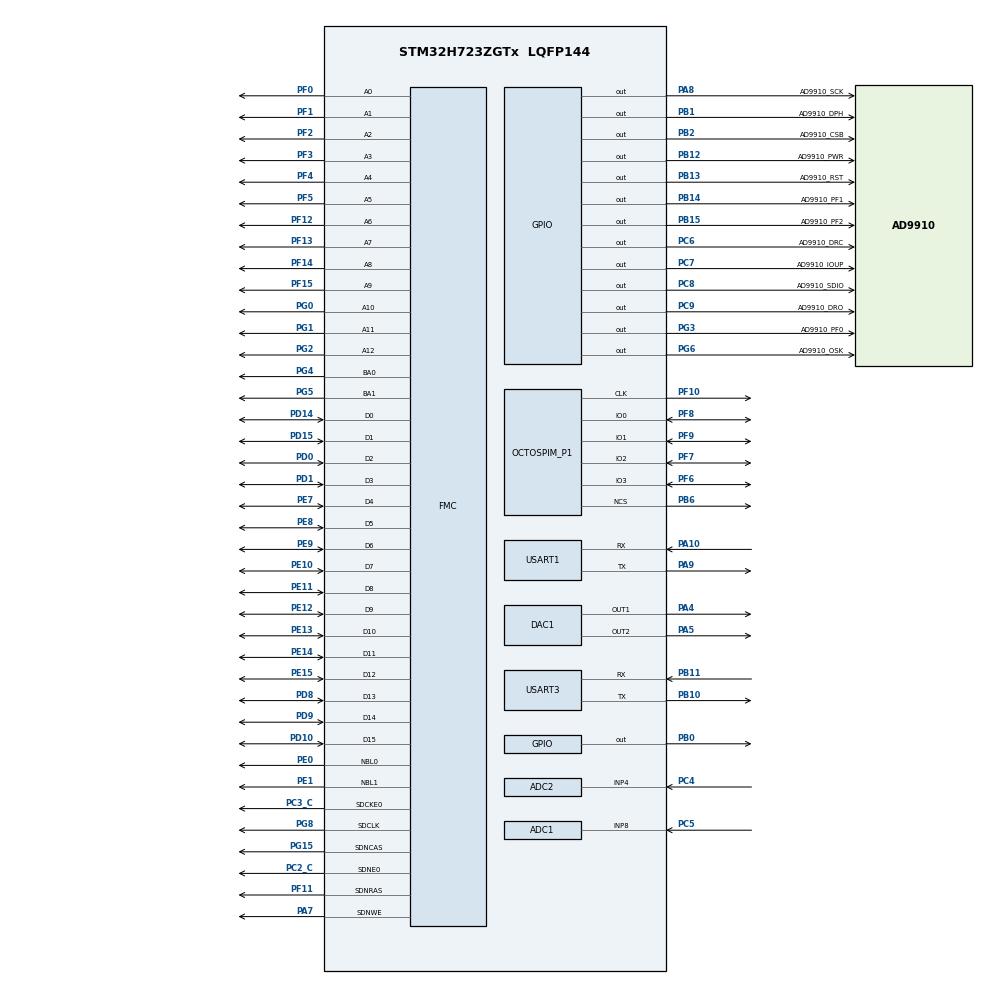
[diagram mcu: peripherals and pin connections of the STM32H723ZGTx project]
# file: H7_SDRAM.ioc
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ADC1.Channel-0\#ChannelRegularConversion=ADC_CHANNEL_8
ADC1.ConversionDataManagement=ADC_CONVERSIONDATA_DMA_ONESHOT
ADC1.ExternalTrigConv=ADC_EXTERNALTRIG_T3_TRGO
ADC1.NbrOfConversionFlag=1
ADC1.OffsetNumber-0\#ChannelRegularConversion=ADC_OFFSET_NONE
ADC1.OffsetSignedSaturation-0\#ChannelRegularConversion=DISABLE
ADC1.Rank-0\#ChannelRegularConversion=1
ADC1.Resolution=ADC_RESOLUTION_12B
ADC1.SamplingTime-0\#ChannelRegularConversion=ADC_SAMPLETIME_2CYCLES_5
ADC1.master=1
ADC2.Channel-0\#ChannelRegularConversion=ADC_CHANNEL_4
ADC2.ClockPrescaler=ADC_CLOCK_ASYNC_DIV1
ADC2.ConversionDataManagement=ADC_CONVERSIONDATA_DMA_ONESHOT
ADC2.ExternalTrigConv=ADC_EXTERNALTRIG_T3_TRGO
ADC2.NbrOfConversionFlag=1
ADC2.OffsetNumber-0\#ChannelRegularConversion=ADC_OFFSET_NONE
ADC2.OffsetSignedSaturation-0\#ChannelRegularConversion=DISABLE
ADC2.Rank-0\#ChannelRegularConversion=1
ADC2.Resolution=ADC_RESOLUTION_12B
ADC2.SamplingTime-0\#ChannelRegularConversion=ADC_SAMPLETIME_2CYCLES_5
CORTEX_M7.AccessPermission_S-Cortex_Memory_Protection_Unit_Region1_Settings_S=MPU_REGION_FULL_ACCESS
CORTEX_M7.AccessPermission_S-Cortex_Memory_Protection_Unit_Region2_Settings_S=MPU_REGION_FULL_ACCESS
CORTEX_M7.AccessPermission_S-Cortex_Memory_Protection_Unit_Region3_Settings_S=MPU_REGION_FULL_ACCESS
CORTEX_M7.AccessPermission_S-Cortex_Memory_Protection_Unit_Region5_Settings_S=MPU_REGION_FULL_ACCESS
CORTEX_M7.AccessPermission_Spec=MPU_REGION_FULL_ACCESS
CORTEX_M7.BaseAddress_S-Cortex_Memory_Protection_Unit_Region1_Settings_S=0x60000000
CORTEX_M7.BaseAddress_S-Cortex_Memory_Protection_Unit_Region2_Settings_S=0x30000000
CORTEX_M7.BaseAddress_S-Cortex_Memory_Protection_Unit_Region3_Settings_S=0x38000000
CORTEX_M7.BaseAddress_S-Cortex_Memory_Protection_Unit_Region5_Settings_S=0xC0000000
CORTEX_M7.BaseAddress_Spec=0x24000000
CORTEX_M7.CPU_DCache=Enabled
CORTEX_M7.CPU_ICache=Enabled
CORTEX_M7.DisableExec_S-Cortex_Memory_Protection_Unit_Region1_Settings_S=MPU_INSTRUCTION_ACCESS_ENABLE
CORTEX_M7.DisableExec_S-Cortex_Memory_Protection_Unit_Region2_Settings_S=MPU_INSTRUCTION_ACCESS_ENABLE
CORTEX_M7.DisableExec_S-Cortex_Memory_Protection_Unit_Region3_Settings_S=MPU_INSTRUCTION_ACCESS_ENABLE
CORTEX_M7.DisableExec_Spec=MPU_INSTRUCTION_ACCESS_ENABLE
CORTEX_M7.Enable_S-Cortex_Memory_Protection_Unit_Region1_Settings_S=MPU_REGION_ENABLE
CORTEX_M7.Enable_S-Cortex_Memory_Protection_Unit_Region2_Settings_S=MPU_REGION_ENABLE
CORTEX_M7.Enable_S-Cortex_Memory_Protection_Unit_Region3_Settings_S=MPU_REGION_ENABLE
CORTEX_M7.Enable_S-Cortex_Memory_Protection_Unit_Region4_Settings_S=__NULL
CORTEX_M7.Enable_S-Cortex_Memory_Protection_Unit_Region5_Settings_S=MPU_REGION_ENABLE
CORTEX_M7.IsBufferable_S-Cortex_Memory_Protection_Unit_Region1_Settings_S=MPU_ACCESS_BUFFERABLE
CORTEX_M7.IsBufferable_S-Cortex_Memory_Protection_Unit_Region2_Settings_S=MPU_ACCESS_BUFFERABLE
CORTEX_M7.IsBufferable_Spec=MPU_ACCESS_BUFFERABLE
CORTEX_M7.IsCacheable_S-Cortex_Memory_Protection_Unit_Region1_Settings_S=MPU_ACCESS_NOT_CACHEABLE
CORTEX_M7.IsCacheable_S-Cortex_Memory_Protection_Unit_Region2_Settings_S=MPU_ACCESS_CACHEABLE
CORTEX_M7.IsCacheable_S-Cortex_Memory_Protection_Unit_Region3_Settings_S=MPU_ACCESS_CACHEABLE
CORTEX_M7.IsCacheable_S-Cortex_Memory_Protection_Unit_Region5_Settings_S=MPU_ACCESS_CACHEABLE
CORTEX_M7.IsCacheable_Spec=MPU_ACCESS_CACHEABLE
CORTEX_M7.IsShareable_Spec=MPU_ACCESS_NOT_SHAREABLE
CORTEX_M7.Size_S-Cortex_Memory_Protection_Unit_Region1_Settings_S=MPU_REGION_SIZE_64KB
CORTEX_M7.Size_S-Cortex_Memory_Protection_Unit_Region2_Settings_S=MPU_REGION_SIZE_64KB
CORTEX_M7.Size_S-Cortex_Memory_Protection_Unit_Region3_Settings_S=MPU_REGION_SIZE_64KB
CORTEX_M7.Size_S-Cortex_Memory_Protection_Unit_Region5_Settings_S=MPU_REGION_SIZE_32MB
CORTEX_M7.Size_Spec=MPU_REGION_SIZE_512KB
CORTEX_M7.SubRegionDisable_S-Cortex_Memory_Protection_Unit_Region1_Settings_S=0x00
CORTEX_M7.SubRegionDisable_Spec=0xE0
CORTEX_M7.TypeExtField_S-Cortex_Memory_Protection_Unit_Region1_Settings_S=MPU_TEX_LEVEL1
CORTEX_M7.TypeExtField_S-Cortex_Memory_Protection_Unit_Region5_Settings_S=MPU_TEX_LEVEL1
CORTEX_M7.TypeExtField_Spec=MPU_TEX_LEVEL1
CORTEX_M7.default_mode_Activation=1
DAC1.DAC_Channel-DAC_OUT1=DAC_CHANNEL_1
DAC1.DAC_Channel-DAC_OUT2=DAC_CHANNEL_2
DAC1.DAC_Trigger-DAC_OUT1=DAC_TRIGGER_T4_TRGO
DAC1.DAC_Trigger-DAC_OUT2=DAC_TRIGGER_T4_TRGO
Dma.ADC1.0.Direction=DMA_PERIPH_TO_MEMORY
Dma.ADC1.0.EventEnable=DISABLE
Dma.ADC1.0.FIFOMode=DMA_FIFOMODE_DISABLE
Dma.ADC1.0.Instance=DMA1_Stream0
Dma.ADC1.0.MemDataAlignment=DMA_MDATAALIGN_HALFWORD
Dma.ADC1.0.MemInc=DMA_MINC_ENABLE
Dma.ADC1.0.Mode=DMA_NORMAL
Dma.ADC1.0.PeriphDataAlignment=DMA_PDATAALIGN_HALFWORD
Dma.ADC1.0.PeriphInc=DMA_PINC_DISABLE
Dma.ADC1.0.Polarity=HAL_DMAMUX_REQ_GEN_RISING
Dma.ADC1.0.Priority=DMA_PRIORITY_HIGH
Dma.ADC1.0.RequestNumber=1
Dma.ADC1.0.SignalID=NONE
Dma.ADC1.0.SyncEnable=DISABLE
Dma.ADC1.0.SyncPolarity=HAL_DMAMUX_SYNC_NO_EVENT
Dma.ADC1.0.SyncRequestNumber=1
Dma.ADC1.0.SyncSignalID=NONE
Dma.ADC2.3.Direction=DMA_PERIPH_TO_MEMORY
Dma.ADC2.3.EventEnable=DISABLE
Dma.ADC2.3.FIFOMode=DMA_FIFOMODE_DISABLE
Dma.ADC2.3.Instance=DMA1_Stream3
Dma.ADC2.3.MemDataAlignment=DMA_MDATAALIGN_HALFWORD
Dma.ADC2.3.MemInc=DMA_MINC_ENABLE
Dma.ADC2.3.Mode=DMA_NORMAL
Dma.ADC2.3.PeriphDataAlignment=DMA_PDATAALIGN_HALFWORD
Dma.ADC2.3.PeriphInc=DMA_PINC_DISABLE
Dma.ADC2.3.Polarity=HAL_DMAMUX_REQ_GEN_RISING
Dma.ADC2.3.Priority=DMA_PRIORITY_HIGH
Dma.ADC2.3.RequestNumber=1
Dma.ADC2.3.SignalID=NONE
Dma.ADC2.3.SyncEnable=DISABLE
Dma.ADC2.3.SyncPolarity=HAL_DMAMUX_SYNC_NO_EVENT
Dma.ADC2.3.SyncRequestNumber=1
Dma.ADC2.3.SyncSignalID=NONE
Dma.DAC1_CH1.4.Direction=DMA_MEMORY_TO_PERIPH
Dma.DAC1_CH1.4.EventEnable=DISABLE
Dma.DAC1_CH1.4.FIFOMode=DMA_FIFOMODE_DISABLE
Dma.DAC1_CH1.4.Instance=DMA1_Stream4
Dma.DAC1_CH1.4.MemDataAlignment=DMA_MDATAALIGN_HALFWORD
Dma.DAC1_CH1.4.MemInc=DMA_MINC_ENABLE
Dma.DAC1_CH1.4.Mode=DMA_CIRCULAR
Dma.DAC1_CH1.4.PeriphDataAlignment=DMA_PDATAALIGN_HALFWORD
Dma.DAC1_CH1.4.PeriphInc=DMA_PINC_DISABLE
Dma.DAC1_CH1.4.Polarity=HAL_DMAMUX_REQ_GEN_RISING
Dma.DAC1_CH1.4.Priority=DMA_PRIORITY_LOW
Dma.DAC1_CH1.4.RequestNumber=1
Dma.DAC1_CH1.4.SignalID=NONE
Dma.DAC1_CH1.4.SyncEnable=DISABLE
Dma.DAC1_CH1.4.SyncPolarity=HAL_DMAMUX_SYNC_NO_EVENT
Dma.DAC1_CH1.4.SyncRequestNumber=1
Dma.DAC1_CH1.4.SyncSignalID=NONE
Dma.DAC1_CH2.5.Direction=DMA_MEMORY_TO_PERIPH
Dma.DAC1_CH2.5.EventEnable=DISABLE
Dma.DAC1_CH2.5.FIFOMode=DMA_FIFOMODE_DISABLE
Dma.DAC1_CH2.5.Instance=DMA1_Stream5
Dma.DAC1_CH2.5.MemDataAlignment=DMA_MDATAALIGN_HALFWORD
Dma.DAC1_CH2.5.MemInc=DMA_MINC_ENABLE
Dma.DAC1_CH2.5.Mode=DMA_CIRCULAR
Dma.DAC1_CH2.5.PeriphDataAlignment=DMA_PDATAALIGN_HALFWORD
Dma.DAC1_CH2.5.PeriphInc=DMA_PINC_DISABLE
Dma.DAC1_CH2.5.Polarity=HAL_DMAMUX_REQ_GEN_RISING
Dma.DAC1_CH2.5.Priority=DMA_PRIORITY_LOW
Dma.DAC1_CH2.5.RequestNumber=1
Dma.DAC1_CH2.5.SignalID=NONE
Dma.DAC1_CH2.5.SyncEnable=DISABLE
Dma.DAC1_CH2.5.SyncPolarity=HAL_DMAMUX_SYNC_NO_EVENT
Dma.DAC1_CH2.5.SyncRequestNumber=1
Dma.DAC1_CH2.5.SyncSignalID=NONE
Dma.Request0=ADC1
Dma.Request1=USART1_RX
Dma.Request2=USART3_RX
Dma.Request3=ADC2
Dma.Request4=DAC1_CH1
Dma.Request5=DAC1_CH2
Dma.USART1_RX.1.Direction=DMA_PERIPH_TO_MEMORY
Dma.USART1_RX.1.EventEnable=DISABLE
Dma.USART1_RX.1.FIFOMode=DMA_FIFOMODE_DISABLE
Dma.USART1_RX.1.Instance=DMA1_Stream1
Dma.USART1_RX.1.MemDataAlignment=DMA_MDATAALIGN_BYTE
Dma.USART1_RX.1.MemInc=DMA_MINC_ENABLE
Dma.USART1_RX.1.Mode=DMA_NORMAL
Dma.USART1_RX.1.PeriphDataAlignment=DMA_PDATAALIGN_BYTE
Dma.USART1_RX.1.PeriphInc=DMA_PINC_DISABLE
Dma.USART1_RX.1.Polarity=HAL_DMAMUX_REQ_GEN_RISING
Dma.USART1_RX.1.Priority=DMA_PRIORITY_HIGH
Dma.USART1_RX.1.RequestNumber=1
Dma.USART1_RX.1.SignalID=NONE
Dma.USART1_RX.1.SyncEnable=DISABLE
Dma.USART1_RX.1.SyncPolarity=HAL_DMAMUX_SYNC_NO_EVENT
Dma.USART1_RX.1.SyncRequestNumber=1
Dma.USART1_RX.1.SyncSignalID=NONE
Dma.USART3_RX.2.Direction=DMA_PERIPH_TO_MEMORY
Dma.USART3_RX.2.EventEnable=DISABLE
Dma.USART3_RX.2.FIFOMode=DMA_FIFOMODE_DISABLE
Dma.USART3_RX.2.Instance=DMA1_Stream2
Dma.USART3_RX.2.MemDataAlignment=DMA_MDATAALIGN_BYTE
Dma.USART3_RX.2.MemInc=DMA_MINC_ENABLE
Dma.USART3_RX.2.Mode=DMA_NORMAL
Dma.USART3_RX.2.PeriphDataAlignment=DMA_PDATAALIGN_BYTE
Dma.USART3_RX.2.PeriphInc=DMA_PINC_DISABLE
Dma.USART3_RX.2.Polarity=HAL_DMAMUX_REQ_GEN_RISING
Dma.USART3_RX.2.Priority=DMA_PRIORITY_HIGH
Dma.USART3_RX.2.RequestNumber=1
Dma.USART3_RX.2.SignalID=NONE
Dma.USART3_RX.2.SyncEnable=DISABLE
Dma.USART3_RX.2.SyncPolarity=HAL_DMAMUX_SYNC_NO_EVENT
Dma.USART3_RX.2.SyncRequestNumber=1
Dma.USART3_RX.2.SyncSignalID=NONE
FMC.CASLatency1=FMC_SDRAM_CAS_LATENCY_3
FMC.ColumnBitsNumber1=FMC_SDRAM_COLUMN_BITS_NUM_9
FMC.ExitSelfRefreshDelay1=10
FMC.LoadToActiveDelay1=2
FMC.RCDDelay1=2
FMC.RPDelay1=3
FMC.RPDelay2=3
FMC.ReadBurst1=FMC_SDRAM_RBURST_ENABLE
FMC.ReadPipeDelay1=FMC_SDRAM_RPIPE_DELAY_1
FMC.ReadPipeDelay2=FMC_SDRAM_RPIPE_DELAY_1
FMC.RowCycleDelay1=9
FMC.RowCycleDelay2=9
FMC.SDClockPeriod1=FMC_SDRAM_CLOCK_PERIOD_2
FMC.SelfRefreshTime1=6
FMC.WriteRecoveryTime1=4
Mcu.Family=STM32H7
Mcu.Name=STM32H723ZGTx
Mcu.Package=LQFP144
NVIC.ADC_IRQn=true\:1\:0\:true\:false\:true\:true\:true\:true
NVIC.DMA1_Stream0_IRQn=true\:0\:0\:false\:false\:true\:false\:true\:true
NVIC.DMA1_Stream1_IRQn=true\:1\:0\:true\:false\:true\:false\:true\:true
NVIC.DMA1_Stream2_IRQn=true\:0\:0\:false\:false\:true\:false\:true\:true
NVIC.DMA1_Stream3_IRQn=true\:0\:0\:false\:false\:true\:false\:true\:true
NVIC.DMA1_Stream4_IRQn=true\:0\:0\:false\:false\:true\:false\:true\:true
NVIC.DMA1_Stream5_IRQn=true\:0\:0\:false\:false\:true\:false\:true\:true
NVIC.PriorityGroup=NVIC_PRIORITYGROUP_4
NVIC.TIM4_IRQn=true\:0\:0\:false\:false\:true\:true\:true\:true
NVIC.TIM6_DAC_IRQn=true\:0\:0\:false\:false\:true\:true\:true\:true
NVIC.USART1_IRQn=true\:0\:0\:false\:false\:true\:true\:true\:true
NVIC.USART3_IRQn=true\:0\:0\:false\:false\:true\:true\:true\:true
OCTOSPI1.ChipSelectHighTime=4
OCTOSPI1.ClockPrescaler=3
OCTOSPI1.DeviceSize=23
OCTOSPI1.FifoThreshold=4
OCTOSPI1.SampleShifting=HAL_OSPI_SAMPLE_SHIFTING_HALFCYCLE
PA10.Mode=Asynchronous
PA10.Signal=USART1_RX
PA4.Signal=COMP_DAC11_group
PA5.Signal=COMP_DAC12_group
PA7.Signal=FMC_SDNWE
PA8.GPIO_Label=AD9910_SCK
PA8.GPIO_Speed=GPIO_SPEED_FREQ_HIGH
PA8.Signal=GPIO_Output
PA9.Mode=Asynchronous
PA9.Signal=USART1_TX
PB0.GPIO_Speed=GPIO_SPEED_FREQ_VERY_HIGH
PB0.PinState=GPIO_PIN_SET
PB0.Signal=GPIO_Output
PB1.GPIO_Label=AD9910_DPH
PB1.GPIO_Speed=GPIO_SPEED_FREQ_HIGH
PB1.Signal=GPIO_Output
PB10.Mode=Asynchronous
PB10.Signal=USART3_TX
PB11.Mode=Asynchronous
PB11.Signal=USART3_RX
PB12.GPIO_Label=AD9910_PWR
PB12.GPIO_Speed=GPIO_SPEED_FREQ_HIGH
PB12.Signal=GPIO_Output
PB13.GPIO_Label=AD9910_RST
PB13.GPIO_Speed=GPIO_SPEED_FREQ_HIGH
PB13.Signal=GPIO_Output
PB14.GPIO_Label=AD9910_PF1
PB14.GPIO_Speed=GPIO_SPEED_FREQ_HIGH
PB14.Signal=GPIO_Output
PB15.GPIO_Label=AD9910_PF2
PB15.GPIO_Speed=GPIO_SPEED_FREQ_HIGH
PB15.Signal=GPIO_Output
PB2.GPIO_Label=AD9910_CSB
PB2.GPIO_Speed=GPIO_SPEED_FREQ_HIGH
PB2.Signal=GPIO_Output
PB6.Mode=OCTOSPI1_Port1_NCS
PB6.Signal=OCTOSPIM_P1_NCS
PC14-OSC32_IN.Mode=LSE-External-Oscillator
PC14-OSC32_IN.Signal=RCC_OSC32_IN
PC15-OSC32_OUT.Mode=LSE-External-Oscillator
PC15-OSC32_OUT.Signal=RCC_OSC32_OUT
PC2_C.Mode=SdramChipSelect1_1
PC2_C.Signal=FMC_SDNE0
PC3_C.Mode=SdramChipSelect1_1
PC3_C.Signal=FMC_SDCKE0
PC4.Signal=ADCx_INP4
PC5.Signal=ADCx_INP8
PC6.GPIO_Label=AD9910_DRC
PC6.GPIO_Speed=GPIO_SPEED_FREQ_HIGH
PC6.Signal=GPIO_Output
PC7.GPIO_Label=AD9910_IOUP
PC7.GPIO_Speed=GPIO_SPEED_FREQ_HIGH
PC7.Signal=GPIO_Output
PC8.GPIO_Label=AD9910_SDIO
PC8.GPIO_Speed=GPIO_SPEED_FREQ_HIGH
PC8.Signal=GPIO_Output
PC9.GPIO_Label=AD9910_DRO
PC9.GPIO_Speed=GPIO_SPEED_FREQ_HIGH
PC9.Signal=GPIO_Output
PD0.Signal=FMC_D2_DA2
PD1.Signal=FMC_D3_DA3
PD10.Signal=FMC_D15_DA15
PD14.Signal=FMC_D0_DA0
PD15.Signal=FMC_D1_DA1
PD8.Signal=FMC_D13_DA13
PD9.Signal=FMC_D14_DA14
PE0.Signal=FMC_NBL0
PE1.Signal=FMC_NBL1
PE10.Signal=FMC_D7_DA7
PE11.Signal=FMC_D8_DA8
PE12.Signal=FMC_D9_DA9
PE13.Signal=FMC_D10_DA10
PE14.Signal=FMC_D11_DA11
PE15.Signal=FMC_D12_DA12
PE7.Signal=FMC_D4_DA4
PE8.Signal=FMC_D5_DA5
PE9.Signal=FMC_D6_DA6
PF0.Signal=FMC_A0
PF1.Signal=FMC_A1
PF10.Mode=O1_P1_CLK
PF10.Signal=OCTOSPIM_P1_CLK
PF11.Signal=FMC_SDNRAS
PF12.Signal=FMC_A6
PF13.Signal=FMC_A7
PF14.Signal=FMC_A8
PF15.Signal=FMC_A9
PF2.Signal=FMC_A2
PF3.Signal=FMC_A3
PF4.Signal=FMC_A4
PF5.Signal=FMC_A5
PF6.Mode=OCTOSPI1_IOL_Port1L
PF6.Signal=OCTOSPIM_P1_IO3
PF7.Mode=OCTOSPI1_IOL_Port1L
PF7.Signal=OCTOSPIM_P1_IO2
PF8.Mode=OCTOSPI1_IOL_Port1L
PF8.Signal=OCTOSPIM_P1_IO0
PF9.Mode=OCTOSPI1_IOL_Port1L
PF9.Signal=OCTOSPIM_P1_IO1
PG0.Signal=FMC_A10
PG1.Signal=FMC_A11
PG15.Signal=FMC_SDNCAS
PG2.Signal=FMC_A12
PG3.GPIO_Label=AD9910_PF0
PG3.GPIO_Speed=GPIO_SPEED_FREQ_HIGH
PG3.Signal=GPIO_Output
PG4.Signal=FMC_A14_BA0
PG5.Signal=FMC_A15_BA1
PG6.GPIO_Label=AD9910_OSK
PG6.GPIO_Speed=GPIO_SPEED_FREQ_HIGH
PG6.Signal=GPIO_Output
PG8.Signal=FMC_SDCLK
PH0-OSC_IN.Mode=HSE-External-Oscillator
PH0-OSC_IN.Signal=RCC_OSC_IN
PH1-OSC_OUT.Mode=HSE-External-Oscillator
PH1-OSC_OUT.Signal=RCC_OSC_OUT
ProjectManager.HeapSize=0x4000
ProjectManager.StackSize=0x4000
ProjectManager.TargetToolchain=MDK-ARM V5.32
RCC.ADCFreq_Value=129000000
RCC.APB1Freq_Value=137500000
RCC.APB2Freq_Value=137500000
RCC.APB3Freq_Value=137500000
RCC.APB4Freq_Value=137500000
RCC.CortexFreq_Value=550000000
RCC.D1PPRE=RCC_APB3_DIV2
RCC.D2PPRE1=RCC_APB1_DIV2
RCC.D2PPRE2=RCC_APB2_DIV2
RCC.D3PPRE=RCC_APB4_DIV2
RCC.DIVM1=4
RCC.DIVN1=34
RCC.DIVP1=1
RCC.HCLKFreq_Value=275000000
RCC.HPRE=RCC_HCLK_DIV2
RCC.PLL2FRACN=0
RCC.PLL3FRACN=0
RCC.PLLFRACN=3072
RCC.SYSCLKFreq_VALUE=550000000
RCC.SYSCLKSource=RCC_SYSCLKSOURCE_PLLCLK
RCC.USBFreq_Value=275000000
SH.ADCx_INP4.0=ADC2_INP4,IN4-Single-Ended
SH.ADCx_INP8.0=ADC1_INP8,IN8-Single-Ended
SH.COMP_DAC11_group.0=DAC1_OUT1,DAC_OUT1
SH.COMP_DAC12_group.0=DAC1_OUT2,DAC_OUT2
SH.FMC_A0.0=FMC_A0,13b-sda1
SH.FMC_A1.0=FMC_A1,13b-sda1
SH.FMC_A10.0=FMC_A10,13b-sda1
SH.FMC_A11.0=FMC_A11,13b-sda1
SH.FMC_A12.0=FMC_A12,13b-sda1
SH.FMC_A14_BA0.0=FMC_BA0,FourSdramBanks1
SH.FMC_A15_BA1.0=FMC_BA1,FourSdramBanks1
SH.FMC_A2.0=FMC_A2,13b-sda1
SH.FMC_A3.0=FMC_A3,13b-sda1
SH.FMC_A4.0=FMC_A4,13b-sda1
SH.FMC_A5.0=FMC_A5,13b-sda1
SH.FMC_A6.0=FMC_A6,13b-sda1
SH.FMC_A7.0=FMC_A7,13b-sda1
SH.FMC_A8.0=FMC_A8,13b-sda1
SH.FMC_A9.0=FMC_A9,13b-sda1
SH.FMC_D0_DA0.0=FMC_D0,sd-16b-d1
SH.FMC_D10_DA10.0=FMC_D10,sd-16b-d1
SH.FMC_D11_DA11.0=FMC_D11,sd-16b-d1
SH.FMC_D12_DA12.0=FMC_D12,sd-16b-d1
SH.FMC_D13_DA13.0=FMC_D13,sd-16b-d1
SH.FMC_D14_DA14.0=FMC_D14,sd-16b-d1
SH.FMC_D15_DA15.0=FMC_D15,sd-16b-d1
SH.FMC_D1_DA1.0=FMC_D1,sd-16b-d1
SH.FMC_D2_DA2.0=FMC_D2,sd-16b-d1
SH.FMC_D3_DA3.0=FMC_D3,sd-16b-d1
SH.FMC_D4_DA4.0=FMC_D4,sd-16b-d1
SH.FMC_D5_DA5.0=FMC_D5,sd-16b-d1
SH.FMC_D6_DA6.0=FMC_D6,sd-16b-d1
SH.FMC_D7_DA7.0=FMC_D7,sd-16b-d1
SH.FMC_D8_DA8.0=FMC_D8,sd-16b-d1
SH.FMC_D9_DA9.0=FMC_D9,sd-16b-d1
SH.FMC_NBL0.0=FMC_NBL0,Sd2ByteEnable1
SH.FMC_NBL1.0=FMC_NBL1,Sd2ByteEnable1
SH.FMC_SDCLK.0=FMC_SDCLK,13b-sda1
SH.FMC_SDNCAS.0=FMC_SDNCAS,13b-sda1
SH.FMC_SDNRAS.0=FMC_SDNRAS,13b-sda1
SH.FMC_SDNWE.0=FMC_SDNWE,13b-sda1
TIM3.AutoReloadPreload=TIM_AUTORELOAD_PRELOAD_ENABLE
TIM3.Period=11-1
TIM3.Prescaler=25-1
TIM3.TIM_MasterOutputTrigger=TIM_TRGO_UPDATE
TIM4.AutoReloadPreload=TIM_AUTORELOAD_PRELOAD_ENABLE
TIM4.Period=5-1
TIM4.Prescaler=8-1
TIM4.TIM_MasterOutputTrigger=TIM_TRGO_UPDATE
USART1.VirtualMode-Asynchronous=VM_ASYNC
USART3.VirtualMode-Asynchronous=VM_ASYNC
VP_MEMORYMAP_VS_MEMORYMAP.Mode=CurAppReg
VP_OCTOSPI1_VS_quad.Mode=quad_mode
VP_TIM3_VS_ClockSourceINT.Mode=Internal
VP_TIM4_VS_ClockSourceINT.Mode=Internal
board=custom

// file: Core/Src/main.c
/* USER CODE BEGIN Header */
/**
  ******************************************************************************
  * @file           : main.c
  * @brief          : Main program body
  ******************************************************************************
  * @attention
  *
  * Copyright (c) 2026 STMicroelectronics.
  * All rights reserved.
  *
  * This software is licensed under terms that can be found in the LICENSE file
  * in the root directory of this software component.
  * If no LICENSE file comes with this software, it is provided AS-IS.
  *
  ******************************************************************************
  */
/* USER CODE END Header */
#include "main.h"
#include "adc.h"
#include "dac.h"
#include "dma.h"
#include "octospi.h"
#include "tim.h"
#include "usart.h"
#include "gpio.h"
#include "fmc.h"

/* USER CODE BEGIN Includes */
#include "bspsysteam.h"

/* USER CODE END Includes */

void SystemClock_Config(void);
void PeriphCommonClock_Config(void);
static void MPU_Config(void);

/* USER CODE BEGIN 0 */

__attribute__((section(".RAM_D1"), aligned(32))) uint16_t adc_1_buffer[FFT_LEN];
__attribute__((section(".RAM_D1"), aligned(32))) uint16_t adc_2_buffer[FFT_LEN];
__attribute__((section(".RAM_D3"))) volatile uint8_t adc1_flag;
__attribute__((section(".RAM_D3")))volatile uint8_t adc2_flag;

__attribute__((section(".RAM_D3"))) float32_t re1;
__attribute__((section(".RAM_D3"))) float32_t im1;
__attribute__((section(".RAM_D3"))) float32_t re2;
__attribute__((section(".RAM_D3"))) float32_t im2;

__attribute__((section(".RAM_D3"))) float32_t phase_1;
__attribute__((section(".RAM_D3"))) float32_t phase_2;
__attribute__((section(".RAM_D3"))) float32_t freq_1;
__attribute__((section(".RAM_D3"))) float32_t freq_2;
__attribute__((section(".RAM_D3"))) float32_t phase_diff;
__attribute__((section(".RAM_D3"))) float32_t phase_diff_deg;

__attribute__((section(".RAM_D3"))) uint32_t dac_freq = 100000;
__attribute__((section(".RAM_D3"))) uint32_t dac_phase=0;
__attribute__((section(".RAM_D3"))) uint32_t dac_amp=800;
/*DMA 整个缓冲区采样完成后*/
void HAL_ADC_ConvCpltCallback(ADC_HandleTypeDef *hadc)
{
	if(hadc->Instance==ADC1)
	{
		if(adc1_flag==0)
			adc1_flag = 1;
	}

	if(hadc->Instance==ADC2)
	{
		if(adc2_flag==0)
			adc2_flag = 1;
	}
}

void FFT_proc(void)
{
		float32_t phase_error = 0.0f;
    if (adc1_flag == 1 && adc2_flag == 1)
    {
        adc1_flag = 0;
        adc2_flag = 0;

        Process_fft(adc_1_buffer,FFT_LEN,&phase_1,&freq_1);
				Process_fft(adc_2_buffer,FFT_LEN,&phase_2,&freq_2);
				phase_diff = phase_1-phase_2;
				if (phase_diff > PI)
				{
				phase_diff -= PI2;
				}
				else if (phase_diff < -PI)
				{
				phase_diff += PI2;
				}
				phase_error = (-0.000362f)*freq_1-(0.02f);
        phase_diff_deg = phase_diff * 180.0f / PI-phase_error;

        UART1_Printf("phase_diff:%.2f deg\r\n", phase_diff_deg);
        UART1_Printf("freq1:%.2f Hz\r\n", freq_1);
				UART1_Printf("freq2:%.2f Hz\r\n", freq_2);

        HAL_ADC_Start_DMA(&hadc1, (uint32_t *)adc_1_buffer, FFT_LEN);
        HAL_ADC_Start_DMA(&hadc2, (uint32_t *)adc_2_buffer, FFT_LEN);
    }
}

/* USER CODE END 0 */

uint32_t dac_last_freq;
uint32_t dac_last_phase;
uint32_t dac_last_amp;
int main(void)
{

  /* MPU Configuration--------------------------------------------------------*/
  MPU_Config();

  /* Enable the CPU Cache */

  /* Enable I-Cache---------------------------------------------------------*/
  SCB_EnableICache();

  /* Enable D-Cache---------------------------------------------------------*/
  SCB_EnableDCache();

  /* MCU Configuration--------------------------------------------------------*/

  /* Reset of all peripherals, Initializes the Flash interface and the Systick. */
  HAL_Init();

  /* Configure the system clock */
  SystemClock_Config();

  /* Configure the peripherals common clocks */
  PeriphCommonClock_Config();

  /* Initialize all configured peripherals */
  MX_GPIO_Init();
  MX_DMA_Init();
  MX_FMC_Init();
  MX_OCTOSPI1_Init();
  MX_USART1_UART_Init();
  MX_TIM3_Init();
  MX_ADC1_Init();
  MX_USART3_UART_Init();
  MX_ADC2_Init();
  MX_DAC1_Init();
  MX_TIM4_Init();
  /* USER CODE BEGIN 2 */
	SRAM_Clock_Enable();    // 如果这个函数确实还需要，放在时钟后

  /* USER CODE END 2 */

  /* Infinite loop */
  /* USER CODE BEGIN WHILE */
	scheduler_Init();

	dsp_fft_init((uint16_t)FFT_LEN);
	DDS_Init();

   /* 输出 10 kHz */
   DDS_SetFrequency(dac_freq);
 dac_last_freq = dac_freq;
   /* 初始相位 0 度 */
   DDS_SetPhaseDeg(dac_phase);
dac_last_phase = dac_phase;
    /* 幅度 80% */
   DDS_SetAmplitudePermille(dac_amp);
dac_last_amp = dac_amp;
   /* DAC 中点偏置 */
   DDS_SetOffset(2048);

  DDS_Start();
	HAL_ADC_Start_DMA(&hadc1, (uint32_t *)adc_1_buffer, FFT_LEN);
	HAL_ADC_Start_DMA(&hadc2, (uint32_t *)adc_2_buffer, FFT_LEN);
	HAL_TIM_Base_Start(&htim3);

  while (1)
  {
    /* USER CODE END WHILE */

    /* USER CODE BEGIN 3 */
	FFT_proc();
		 /* 输出 10 kHz */
		if(dac_freq!=dac_last_freq)
		{
			DDS_SetFrequency(dac_freq);
			dac_last_freq = dac_freq;
		}

		if(dac_phase!=dac_last_phase)
		{
			DDS_SetPhaseDeg(dac_phase);
			dac_last_phase = dac_phase;
		}

		if(dac_amp!=dac_last_amp)
		{
			DDS_SetAmplitudePermille(dac_amp);
			dac_last_amp = dac_amp;
		}

  }
  /* USER CODE END 3 */
}

void SystemClock_Config(void)
{
  RCC_OscInitTypeDef RCC_OscInitStruct = {0};
  RCC_ClkInitTypeDef RCC_ClkInitStruct = {0};

  /** Supply configuration update enable
  */
  HAL_PWREx_ConfigSupply(PWR_LDO_SUPPLY);

  /** Configure the main internal regulator output voltage
  */
  __HAL_PWR_VOLTAGESCALING_CONFIG(PWR_REGULATOR_VOLTAGE_SCALE0);

  while(!__HAL_PWR_GET_FLAG(PWR_FLAG_VOSRDY)) {}

  /** Initializes the RCC Oscillators according to the specified parameters
  * in the RCC_OscInitTypeDef structure.
  */
  RCC_OscInitStruct.OscillatorType = RCC_OSCILLATORTYPE_HSI;
  RCC_OscInitStruct.HSIState = RCC_HSI_DIV1;
  RCC_OscInitStruct.HSICalibrationValue = 64;
  RCC_OscInitStruct.PLL.PLLState = RCC_PLL_ON;
  RCC_OscInitStruct.PLL.PLLSource = RCC_PLLSOURCE_HSI;
  RCC_OscInitStruct.PLL.PLLM = 4;
  RCC_OscInitStruct.PLL.PLLN = 34;
  RCC_OscInitStruct.PLL.PLLP = 1;
  RCC_OscInitStruct.PLL.PLLQ = 2;
  RCC_OscInitStruct.PLL.PLLR = 2;
  RCC_OscInitStruct.PLL.PLLRGE = RCC_PLL1VCIRANGE_3;
  RCC_OscInitStruct.PLL.PLLVCOSEL = RCC_PLL1VCOWIDE;
  RCC_OscInitStruct.PLL.PLLFRACN = 3072;
  if (HAL_RCC_OscConfig(&RCC_OscInitStruct) != HAL_OK)
  {
    Error_Handler();
  }

  /** Initializes the CPU, AHB and APB buses clocks
  */
  RCC_ClkInitStruct.ClockType = RCC_CLOCKTYPE_HCLK|RCC_CLOCKTYPE_SYSCLK
                              |RCC_CLOCKTYPE_PCLK1|RCC_CLOCKTYPE_PCLK2
                              |RCC_CLOCKTYPE_D3PCLK1|RCC_CLOCKTYPE_D1PCLK1;
  RCC_ClkInitStruct.SYSCLKSource = RCC_SYSCLKSOURCE_PLLCLK;
  RCC_ClkInitStruct.SYSCLKDivider = RCC_SYSCLK_DIV1;
  RCC_ClkInitStruct.AHBCLKDivider = RCC_HCLK_DIV2;
  RCC_ClkInitStruct.APB3CLKDivider = RCC_APB3_DIV2;
  RCC_ClkInitStruct.APB1CLKDivider = RCC_APB1_DIV2;
  RCC_ClkInitStruct.APB2CLKDivider = RCC_APB2_DIV2;
  RCC_ClkInitStruct.APB4CLKDivider = RCC_APB4_DIV2;

  if (HAL_RCC_ClockConfig(&RCC_ClkInitStruct, FLASH_LATENCY_3) != HAL_OK)
  {
    Error_Handler();
  }
}

void PeriphCommonClock_Config(void)
{
  RCC_PeriphCLKInitTypeDef PeriphClkInitStruct = {0};

  /** Initializes the peripherals clock
  */
  PeriphClkInitStruct.PeriphClockSelection = RCC_PERIPHCLK_ADC;
  PeriphClkInitStruct.PLL2.PLL2M = 32;
  PeriphClkInitStruct.PLL2.PLL2N = 129;
  PeriphClkInitStruct.PLL2.PLL2P = 2;
  PeriphClkInitStruct.PLL2.PLL2Q = 2;
  PeriphClkInitStruct.PLL2.PLL2R = 2;
  PeriphClkInitStruct.PLL2.PLL2RGE = RCC_PLL2VCIRANGE_1;
  PeriphClkInitStruct.PLL2.PLL2VCOSEL = RCC_PLL2VCOWIDE;
  PeriphClkInitStruct.PLL2.PLL2FRACN = 0;
  PeriphClkInitStruct.AdcClockSelection = RCC_ADCCLKSOURCE_PLL2;
  if (HAL_RCCEx_PeriphCLKConfig(&PeriphClkInitStruct) != HAL_OK)
  {
    Error_Handler();
  }
}

 /* MPU Configuration */

void MPU_Config(void)
{
  MPU_Region_InitTypeDef MPU_InitStruct = {0};

  /* Disables the MPU */
  HAL_MPU_Disable();

  /** Initializes and configures the Region and the memory to be protected
  */
  MPU_InitStruct.Enable = MPU_REGION_ENABLE;
  MPU_InitStruct.Number = MPU_REGION_NUMBER0;
  MPU_InitStruct.BaseAddress = 0x24000000;
  MPU_InitStruct.Size = MPU_REGION_SIZE_512KB;
  MPU_InitStruct.SubRegionDisable = 0xE0;
  MPU_InitStruct.TypeExtField = MPU_TEX_LEVEL1;
  MPU_InitStruct.AccessPermission = MPU_REGION_FULL_ACCESS;
  MPU_InitStruct.DisableExec = MPU_INSTRUCTION_ACCESS_ENABLE;
  MPU_InitStruct.IsShareable = MPU_ACCESS_NOT_SHAREABLE;
  MPU_InitStruct.IsCacheable = MPU_ACCESS_CACHEABLE;
  MPU_InitStruct.IsBufferable = MPU_ACCESS_BUFFERABLE;

  HAL_MPU_ConfigRegion(&MPU_InitStruct);

  /** Initializes and configures the Region and the memory to be protected
  */
  MPU_InitStruct.Number = MPU_REGION_NUMBER1;
  MPU_InitStruct.BaseAddress = 0x60000000;
  MPU_InitStruct.Size = MPU_REGION_SIZE_64KB;
  MPU_InitStruct.SubRegionDisable = 0x00;
  MPU_InitStruct.IsCacheable = MPU_ACCESS_NOT_CACHEABLE;

  HAL_MPU_ConfigRegion(&MPU_InitStruct);

  /** Initializes and configures the Region and the memory to be protected
  */
  MPU_InitStruct.Number = MPU_REGION_NUMBER2;
  MPU_InitStruct.BaseAddress = 0x30000000;
  MPU_InitStruct.SubRegionDisable = 0x0;
  MPU_InitStruct.TypeExtField = MPU_TEX_LEVEL0;
  MPU_InitStruct.IsCacheable = MPU_ACCESS_CACHEABLE;

  HAL_MPU_ConfigRegion(&MPU_InitStruct);

  /** Initializes and configures the Region and the memory to be protected
  */
  MPU_InitStruct.Number = MPU_REGION_NUMBER3;
  MPU_InitStruct.BaseAddress = 0x38000000;
  MPU_InitStruct.IsBufferable = MPU_ACCESS_NOT_BUFFERABLE;

  HAL_MPU_ConfigRegion(&MPU_InitStruct);

  /** Initializes and configures the Region and the memory to be protected
  */
  MPU_InitStruct.Number = MPU_REGION_NUMBER5;
  MPU_InitStruct.BaseAddress = 0xC0000000;
  MPU_InitStruct.Size = MPU_REGION_SIZE_32MB;
  MPU_InitStruct.TypeExtField = MPU_TEX_LEVEL1;

  HAL_MPU_ConfigRegion(&MPU_InitStruct);
  /* Enables the MPU */
  HAL_MPU_Enable(MPU_PRIVILEGED_DEFAULT);

}

void Error_Handler(void)
{
  /* USER CODE BEGIN Error_Handler_Debug */
  /* User can add his own implementation to report the HAL error return state */
  __disable_irq();
  while (1)
  {
		HAL_GPIO_TogglePin(GPIOB, GPIO_PIN_0);
        HAL_Delay(100);
  }
  /* USER CODE END Error_Handler_Debug */
}
